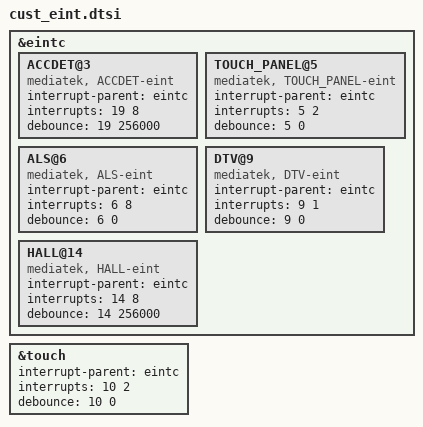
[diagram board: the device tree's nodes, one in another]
/*
 * Generated by MTK SP Drv_CodeGen Version 03.13.6  for MT6735. Copyright MediaTek Inc. (C) 2013.
 * Thu May 28 10:14:14 2015
 * Do Not Modify the File.
 */

/*************************
 * EINT DTSI File
*************************/

#include <dt-bindings/interrupt-controller/irq.h>
#include <dt-bindings/interrupt-controller/arm-gic.h>


&eintc {
	ACCDET@3 {
		compatible = "mediatek, ACCDET-eint";
		interrupt-parent = <&eintc>;
		interrupts = <19 8>;
		debounce = <19 256000>;
	};

	TOUCH_PANEL@5 {
		compatible = "mediatek, TOUCH_PANEL-eint";
		interrupt-parent = <&eintc>;
		interrupts = <5 2>;
		debounce = <5 0>;
	};

	ALS@6 {
		compatible = "mediatek, ALS-eint";
		interrupt-parent = <&eintc>;
		interrupts = <6 8>;
		debounce = <6 0>;
	};

	DTV@9 {
		compatible = "mediatek, DTV-eint";
		interrupt-parent = <&eintc>;
		interrupts = <9 1>;
		debounce = <9 0>;
	};

	HALL@14 {
		compatible = "mediatek, HALL-eint";
		interrupt-parent = <&eintc>;
		interrupts = <14 8>;
		debounce = <14 256000>;
	};

};
&touch {
	interrupt-parent = <&eintc>;
	interrupts = <10 2>;
	debounce = <10 0>;
};
